# STM32WLE5_CM4 register map
File version: 1.4
CPU: CM4 r0p1, little endian, MPU, FPU, 4 interrupt priority bits
Registers are 32-bit, read-write, reset 0x0 unless marked. A register's access mark holds for its fields unless they carry their own. Offsets are from the block's base; [hi:lo] are bit positions; {n}, {i} and the like mark numbered series.

## DMAMUX — DMA request multiplexer
Base 0x40020800
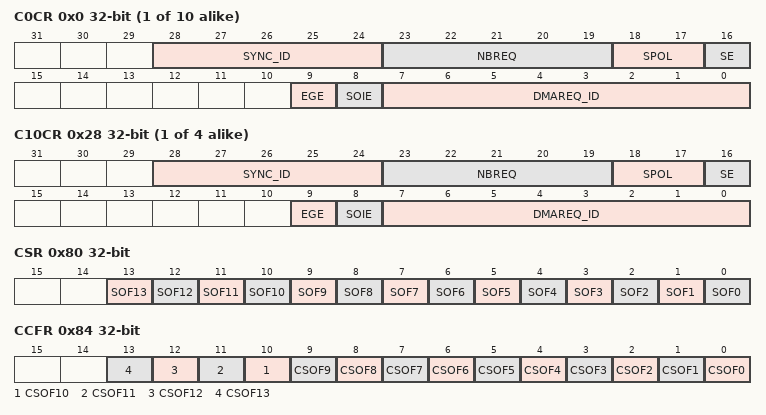
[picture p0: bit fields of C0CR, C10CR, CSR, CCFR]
{0x0+4i} C{i}CR (i=0..9) — request line multiplexer channel x configuration register
  [28:24] SYNC_ID — Synchronization identification
  [23:19] NBREQ — Number of DMA requests minus 1 to forward
  [18:17] SPOL — Synchronization polarity
  [16] SE — Synchronization enable
  [9] EGE — Event generation enable
  [8] SOIE — Synchronization overrun interrupt enable
  [7:0] DMAREQ_ID — DMA request identification
{0x0+4i} C{i}CR (i=10..13)
  [28:24] SYNC_ID, [23:19] NBREQ, [18:17] SPOL, [16] SE, [9] EGE, [8] SOIE, [7:0] DMAREQ_ID
0x80 CSR ro — request line multiplexer interrupt channel status register
  [13] SOF13 — Synchronization overrun event flag
  [n] SOF{n} (n=0..12)
0x84 CCFR wo — request line multiplexer interrupt channel clear flag register
  [n] CSOF{n} (n=0..13)
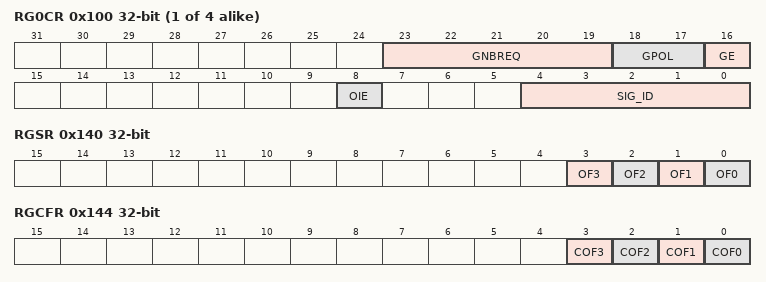
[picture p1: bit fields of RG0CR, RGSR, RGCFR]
{0x100+4i} RG{i}CR (i=0..3) — request generator channel x configuration register
  [23:19] GNBREQ — Number of DMA requests to be generated (minus 1)
  [18:17] GPOL — DMA request generator trigger polarity
  [16] GE — DMA request generator channel x enable
  [8] OIE — Trigger overrun interrupt enable
  [4:0] SIG_ID — Signal identification
0x140 RGSR ro — request generator interrupt status register
  [3] OF3 — Trigger overrun event flag
  [2] OF2
  [1] OF1
  [0] OF0
0x144 RGCFR wo — request generator interrupt clear flag register
  [3] COF3 — Clear trigger overrun event flag
  [2] COF2
  [1] COF1
  [0] COF0

## EXTI — External interrupt/event controller
Base 0x58000800
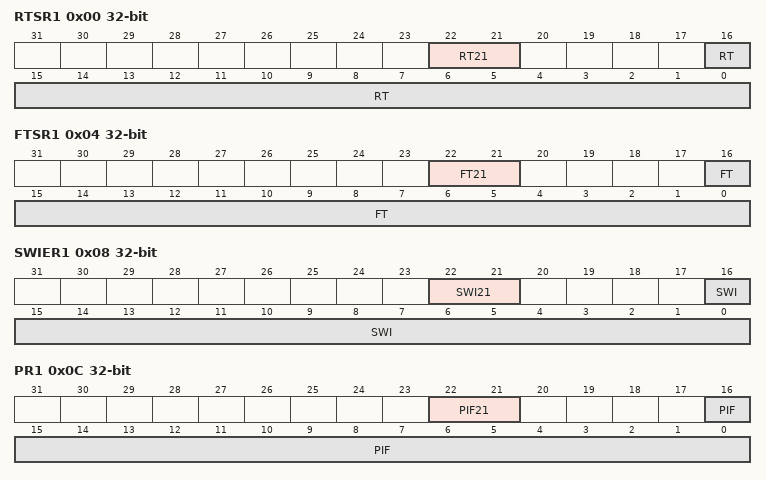
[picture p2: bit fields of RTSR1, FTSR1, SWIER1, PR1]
0x00 RTSR1 — rising trigger selection register
  [22:21] RT21 — Rising trigger event configuration bit of Configurable Event input
  [16:0] RT — Rising trigger event configuration bit of Configurable Event input
0x04 FTSR1 — falling trigger selection register
  [22:21] FT21 — Falling trigger event configuration bit of Configurable Event input
  [16:0] FT — Falling trigger event configuration bit of Configurable Event input
0x08 SWIER1 — software interrupt event register
  [22:21] SWI21 — Software interrupt on event
  [16:0] SWI — Software interrupt on event
0x0C PR1 — EXTI pending register
  [22:21] PIF21 — Configurable event inputs Pending bit
  [16:0] PIF — Configurable event inputs Pending bit
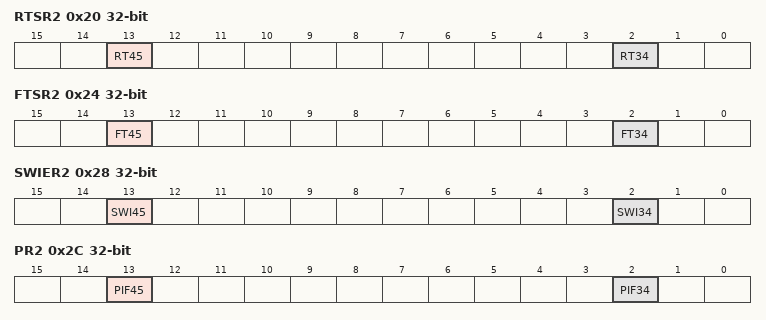
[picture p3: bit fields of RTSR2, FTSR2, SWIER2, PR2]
0x20 RTSR2 — rising trigger selection register
  [13] RT45 — Rising trigger event configuration bit of Configurable Event input
  [2] RT34 — Rising trigger event configuration bit of Configurable Event input
0x24 FTSR2 — falling trigger selection register
  [13] FT45 — Falling trigger event configuration bit of Configurable Event input
  [2] FT34 — Falling trigger event configuration bit of Configurable Event input
0x28 SWIER2 — software interrupt event register
  [13] SWI45 — Software interrupt on event 45
  [2] SWI34 — Software interrupt on event
0x2C PR2 — pending register
  [13] PIF45 — Configurable event inputs 45 Pending bit.
  [2] PIF34 — Configurable event inputs 33 Pending bit.
0x80 IMR1 — interrupt mask register
  [31:0] IM — wakeup with interrupt Mask on event input
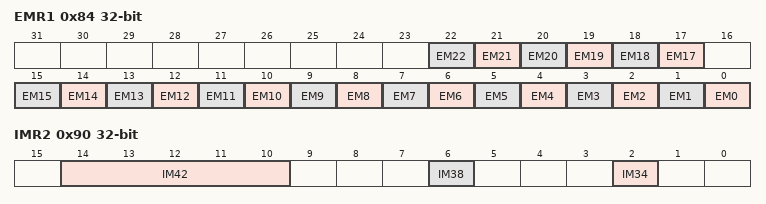
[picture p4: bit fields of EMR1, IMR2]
0x84 EMR1 — event mask register
  [n] EM{n} (n=17..22) — Wakeup with event generation Mask on Event input
  [n] EM{n} (n=0..15) — Wakeup with event generation Mask on Event input
0x90 IMR2 — interrupt mask register
  [14:10] IM42 — CPUm Wakeup with interrupt Mask on Event input
  [6] IM38 — CPUm Wakeup with interrupt Mask on Event input
  [2] IM34 — CPUm Wakeup with interrupt Mask on Event input

## FLASH
Base 0x58004000
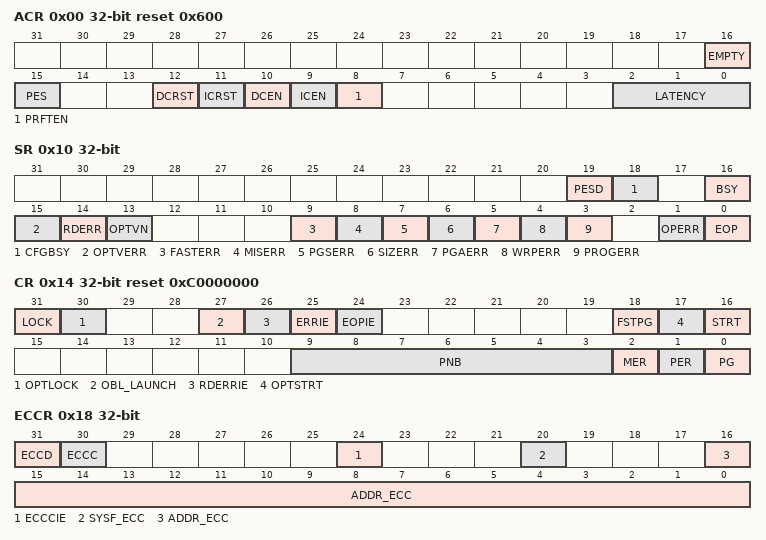
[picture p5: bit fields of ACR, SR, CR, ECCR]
0x00 ACR reset 0x600 — Access control register
  [16] EMPTY — Flash User area empty
  [15] PES — CPU1 programm erase suspend request
  [12] DCRST — Data cache reset
  [11] ICRST — Instruction cache reset
  [10] DCEN — Data cache enable
  [9] ICEN — Instruction cache enable
  [8] PRFTEN — Prefetch enable
  [2:0] LATENCY
0x08 KEYR wo — Flash key register
  [31:0] KEY
0x0C OPTKEYR wo — Option byte key register
  [31:0] OPTKEY — Option byte key
0x10 SR access per field — Status register
  [19] PESD ro — Programming / erase operation suspended
  [18] CFGBSY ro — Programming or erase configuration busy
  [16] BSY ro — Busy
  [15] OPTVERR rw — Option validity error
  [14] RDERR rw — PCROP read error
  [13] OPTVN ro — User Option OPTIVAL indication
  [9] FASTERR rw — Fast programming error
  [8] MISERR rw — Fast programming data miss error
  [7] PGSERR rw — Programming sequence error
  [6] SIZERR rw — Size error
  [5] PGAERR rw — Programming alignment error
  [4] WRPERR rw — Write protected error
  [3] PROGERR rw — Programming error
  [1] OPERR rw — Operation error
  [0] EOP rw — End of operation
0x14 CR reset 0xC0000000 — Flash control register
  [31] LOCK — FLASH_CR Lock
  [30] OPTLOCK — Options Lock
  [27] OBL_LAUNCH — Force the option byte loading
  [26] RDERRIE — PCROP read error interrupt enable
  [25] ERRIE — Error interrupt enable
  [24] EOPIE — End of operation interrupt enable
  [18] FSTPG — Fast programming
  [17] OPTSTRT — Options modification start
  [16] STRT — Start
  [9:3] PNB — Page number
  [2] MER — Mass erase
  [1] PER — Page erase
  [0] PG — Programming
0x18 ECCR access per field — Flash ECC register
  [31] ECCD rw — ECC detection
  [30] ECCC rw — ECC correction
  [24] ECCCIE rw — ECC correction interrupt enable
  [20] SYSF_ECC ro — System Flash ECC fail
  [16:0] ADDR_ECC ro — ECC fail address
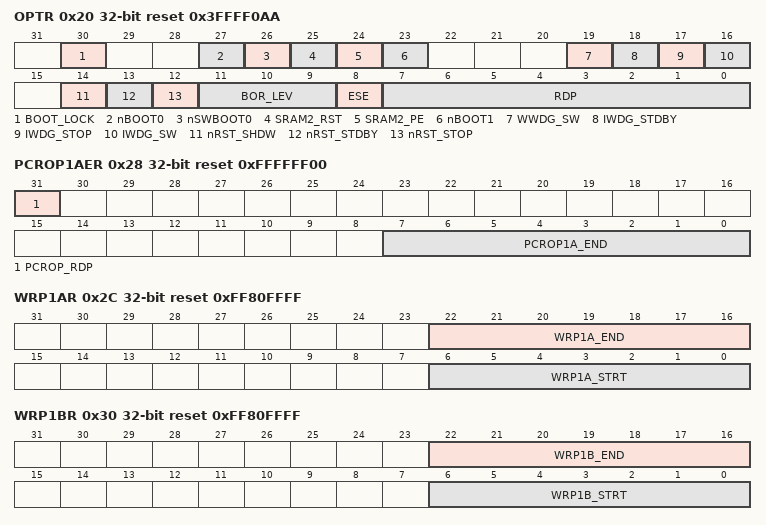
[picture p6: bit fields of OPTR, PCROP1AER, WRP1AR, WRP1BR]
0x20 OPTR reset 0x3FFFF0AA — Flash option register
  [30] BOOT_LOCK — CPU1 CM4 Unique Boot entry enable option bit
  [27] nBOOT0 — nBOOT0 option bit
  [26] nSWBOOT0 — Software BOOT0 selection
  [25] SRAM2_RST — SRAM2 Erase when system reset
  [24] SRAM2_PE — SRAM2 parity check enable
  [23] nBOOT1 — Boot configuration
  [19] WWDG_SW — Window watchdog selection
  [18] IWDG_STDBY — Independent watchdog counter freeze in Standby mode
  [17] IWDG_STOP — Independent watchdog counter freeze in Stop mode
  [16] IWDG_SW — Independent watchdog selection
  [14] nRST_SHDW
  [13] nRST_STDBY
  [12] nRST_STOP
  [11:9] BOR_LEV — BOR reset Level
  [8] ESE — System security enabled flag
  [7:0] RDP — Read protection level
0x24 PCROP1ASR reset 0xFFFFFFFF — Flash PCROP zone A Start address register
  [7:0] PCROP1A_STRT — PCROP1A area start offset
0x28 PCROP1AER reset 0xFFFFFF00 — Flash PCROP zone A End address register
  [31] PCROP_RDP — PCROP area preserved when RDP level decreased
  [7:0] PCROP1A_END — PCROP area end offset
0x2C WRP1AR reset 0xFF80FFFF — Flash WRP area A address register
  [22:16] WRP1A_END — Bank 1 WRP first area A end offset
  [6:0] WRP1A_STRT — Bank 1 WRP first area start offset
0x30 WRP1BR reset 0xFF80FFFF — Flash WRP area B address register
  [22:16] WRP1B_END — Bank 1 WRP second area B start offset
  [6:0] WRP1B_STRT — Bank 1 WRP second area B end offset
0x34 PCROP1BSR reset 0xFFFFFFFF — Flash PCROP zone B Start address register
  [7:0] PCROP1B_STRT — Bank 1 WRP second area B end offset
0x38 PCROP1BER reset 0xFFFFFF00 — Flash PCROP zone B End address register
  [7:0] PCROP1B_END — PCROP1B area end offset

## Notices in the file
Copyright (c) 2020 STMicroelectronics.
SPDX-License-Identifier: Apache-2.0
Licensed under the Apache License, Version 2.0 (the "License");
you may not use this file except in compliance with the License.
You may obtain a copy of the License at
http://www.apache.org/licenses/LICENSE-2.0
Unless required by applicable law or agreed to in writing, software
distributed under the License is distributed on an "AS IS" BASIS,
WITHOUT WARRANTIES OR CONDITIONS OF ANY KIND, either express or implied.
See the License for the specific language governing permissions and
limitations under the License.
